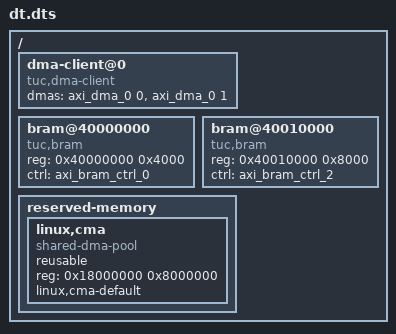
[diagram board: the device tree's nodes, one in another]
/dts-v1/;
/include/ "system-conf.dtsi"
/ {
	dma-client@0 {
		compatible = "tuc,dma-client";
		dmas = <&axi_dma_0 0
			&axi_dma_0 1>;
		dma-names = "tx", "rx";
	};
	bram@40000000 {
		compatible = "tuc,bram";
		reg = <0x40000000 0x4000>;
		ctrl = <&axi_bram_ctrl_0>;
	};
	bram@40010000 {
		compatible = "tuc,bram";
		reg = <0x40010000 0x8000>;
		ctrl = <&axi_bram_ctrl_2>;
	};
	
	reserved-memory {
		#address-cells = <1>;
		#size-cells = <1>;
		ranges;
		linux,cma {
			compatible = "shared-dma-pool";
			reusable;
			reg = <0x18000000 0x8000000>;
			linux,cma-default;
		};
	};
};
